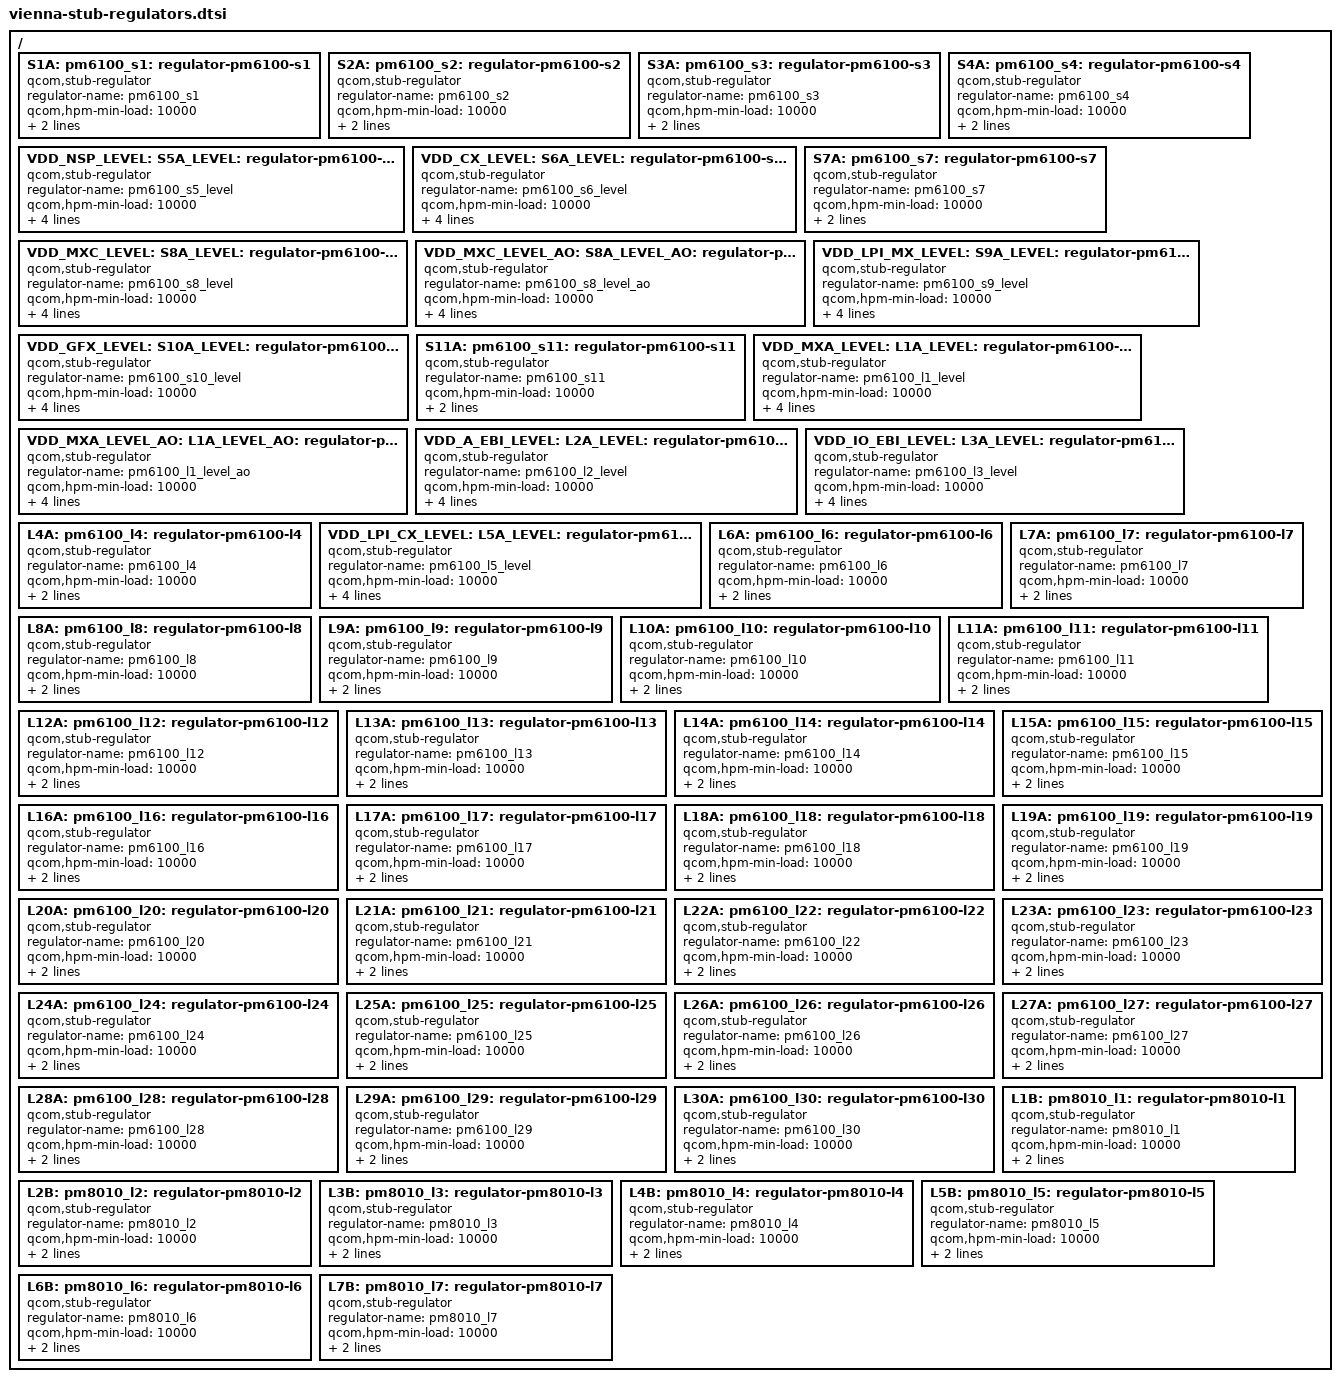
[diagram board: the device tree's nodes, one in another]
// SPDX-License-Identifier: BSD-3-Clause
/*
 * Copyright (c) 2024 Qualcomm Innovation Center, Inc. All rights reserved.
 */

#include <dt-bindings/regulator/qcom,rpmh-regulator-levels.h>

/ {
		S1A:
		pm6100_s1: regulator-pm6100-s1 {
			compatible = "qcom,stub-regulator";
			regulator-name = "pm6100_s1";
			qcom,hpm-min-load = <10000>;
			regulator-min-microvolt = <1700000>;
			regulator-max-microvolt = <1900000>;
		};

		S2A:
		pm6100_s2: regulator-pm6100-s2 {
			compatible = "qcom,stub-regulator";
			regulator-name = "pm6100_s2";
			qcom,hpm-min-load = <10000>;
			regulator-min-microvolt = <1010000>;
			regulator-max-microvolt = <1120000>;
		};

		S3A:
		pm6100_s3: regulator-pm6100-s3 {
			compatible = "qcom,stub-regulator";
			regulator-name = "pm6100_s3";
			qcom,hpm-min-load = <10000>;
			regulator-min-microvolt = <516000>;
			regulator-max-microvolt = <856000>;
		};

		S4A:
		pm6100_s4: regulator-pm6100-s4 {
			compatible = "qcom,stub-regulator";
			regulator-name = "pm6100_s4";
			qcom,hpm-min-load = <10000>;
			regulator-min-microvolt = <516000>;
			regulator-max-microvolt = <856000>;
		};

		VDD_NSP_LEVEL:
		S5A_LEVEL:
		pm6100_s5_level: regulator-pm6100-s5-level {
			compatible = "qcom,stub-regulator";
			regulator-name = "pm6100_s5_level";
			qcom,hpm-min-load = <10000>;
			regulator-min-microvolt =
				<RPMH_REGULATOR_LEVEL_RETENTION>;
			regulator-max-microvolt = <RPMH_REGULATOR_LEVEL_MAX>;
		};

		VDD_CX_LEVEL:
		S6A_LEVEL:
		pm6100_s6_level: regulator-pm6100-s6-level {
			compatible = "qcom,stub-regulator";
			regulator-name = "pm6100_s6_level";
			qcom,hpm-min-load = <10000>;
			regulator-min-microvolt =
				<RPMH_REGULATOR_LEVEL_RETENTION>;
			regulator-max-microvolt = <RPMH_REGULATOR_LEVEL_MAX>;
		};

		S7A:
		pm6100_s7: regulator-pm6100-s7 {
			compatible = "qcom,stub-regulator";
			regulator-name = "pm6100_s7";
			qcom,hpm-min-load = <10000>;
			regulator-min-microvolt = <565000>;
			regulator-max-microvolt = <960000>;
		};

		VDD_MXC_LEVEL:
		S8A_LEVEL:
		pm6100_s8_level: regulator-pm6100-s8-level {
			compatible = "qcom,stub-regulator";
			regulator-name = "pm6100_s8_level";
			qcom,hpm-min-load = <10000>;
			regulator-min-microvolt =
				<RPMH_REGULATOR_LEVEL_RETENTION>;
			regulator-max-microvolt = <RPMH_REGULATOR_LEVEL_MAX>;
		};

		VDD_MXC_LEVEL_AO:
		S8A_LEVEL_AO:
		pm6100_s8_level_ao: regulator-pm6100-s8-level-ao {
			compatible = "qcom,stub-regulator";
			regulator-name = "pm6100_s8_level_ao";
			qcom,hpm-min-load = <10000>;
			regulator-min-microvolt =
				<RPMH_REGULATOR_LEVEL_RETENTION>;
			regulator-max-microvolt = <RPMH_REGULATOR_LEVEL_MAX>;
		};

		VDD_LPI_MX_LEVEL:
		S9A_LEVEL:
		pm6100_s9_level: regulator-pm6100-s9-level {
			compatible = "qcom,stub-regulator";
			regulator-name = "pm6100_s9_level";
			qcom,hpm-min-load = <10000>;
			regulator-min-microvolt =
				<RPMH_REGULATOR_LEVEL_RETENTION>;
			regulator-max-microvolt = <RPMH_REGULATOR_LEVEL_MAX>;
		};

		VDD_GFX_LEVEL:
		S10A_LEVEL:
		pm6100_s10_level: regulator-pm6100-s10-level {
			compatible = "qcom,stub-regulator";
			regulator-name = "pm6100_s10_level";
			qcom,hpm-min-load = <10000>;
			regulator-min-microvolt =
				<RPMH_REGULATOR_LEVEL_RETENTION>;
			regulator-max-microvolt = <RPMH_REGULATOR_LEVEL_MAX>;
		};

		S11A:
		pm6100_s11: regulator-pm6100-s11 {
			compatible = "qcom,stub-regulator";
			regulator-name = "pm6100_s11";
			qcom,hpm-min-load = <10000>;
			regulator-min-microvolt = <1200000>;
			regulator-max-microvolt = <1320000>;
		};

		VDD_MXA_LEVEL:
		L1A_LEVEL:
		pm6100_l1_level: regulator-pm6100-l1-level {
			compatible = "qcom,stub-regulator";
			regulator-name = "pm6100_l1_level";
			qcom,hpm-min-load = <10000>;
			regulator-min-microvolt =
				<RPMH_REGULATOR_LEVEL_RETENTION>;
			regulator-max-microvolt = <RPMH_REGULATOR_LEVEL_MAX>;
		};

		VDD_MXA_LEVEL_AO:
		L1A_LEVEL_AO:
		pm6100_l1_level_ao: regulator-pm6100-l1-level-ao {
			compatible = "qcom,stub-regulator";
			regulator-name = "pm6100_l1_level_ao";
			qcom,hpm-min-load = <10000>;
			regulator-min-microvolt =
				<RPMH_REGULATOR_LEVEL_RETENTION>;
			regulator-max-microvolt = <RPMH_REGULATOR_LEVEL_MAX>;
		};

		VDD_A_EBI_LEVEL:
		L2A_LEVEL:
		pm6100_l2_level: regulator-pm6100-l2-level {
			compatible = "qcom,stub-regulator";
			regulator-name = "pm6100_l2_level";
			qcom,hpm-min-load = <10000>;
			regulator-min-microvolt =
				<RPMH_REGULATOR_LEVEL_RETENTION>;
			regulator-max-microvolt = <RPMH_REGULATOR_LEVEL_MAX>;
		};

		VDD_IO_EBI_LEVEL:
		L3A_LEVEL:
			pm6100_l3_level: regulator-pm6100-l3-level {
			compatible = "qcom,stub-regulator";
			regulator-name = "pm6100_l3_level";
			qcom,hpm-min-load = <10000>;
			regulator-min-microvolt =
				<RPMH_REGULATOR_LEVEL_RETENTION>;
			regulator-max-microvolt = <RPMH_REGULATOR_LEVEL_MAX>;
		};

		L4A:
		pm6100_l4: regulator-pm6100-l4 {
			compatible = "qcom,stub-regulator";
			regulator-name = "pm6100_l4";
			qcom,hpm-min-load = <10000>;
			regulator-min-microvolt = <751000>;
			regulator-max-microvolt = <824000>;
		};

		VDD_LPI_CX_LEVEL:
		L5A_LEVEL:
		pm6100_l5_level: regulator-pm6100-l5-level {
			compatible = "qcom,stub-regulator";
			regulator-name = "pm6100_l5_level";
			qcom,hpm-min-load = <10000>;
			regulator-min-microvolt =
				<RPMH_REGULATOR_LEVEL_RETENTION>;
			regulator-max-microvolt = <RPMH_REGULATOR_LEVEL_MAX>;
		};

		L6A:
		pm6100_l6: regulator-pm6100-l6 {
			compatible = "qcom,stub-regulator";
			regulator-name = "pm6100_l6";
			qcom,hpm-min-load = <10000>;
			regulator-min-microvolt = <1080000>;
			regulator-max-microvolt = <1350000>;
		};

		L7A:
		pm6100_l7: regulator-pm6100-l7 {
			compatible = "qcom,stub-regulator";
			regulator-name = "pm6100_l7";
			qcom,hpm-min-load = <10000>;
			regulator-min-microvolt = <1080000>;
			regulator-max-microvolt = <1320000>;
		};

		L8A:
		pm6100_l8: regulator-pm6100-l8 {
			compatible = "qcom,stub-regulator";
			regulator-name = "pm6100_l8";
			qcom,hpm-min-load = <10000>;
			regulator-min-microvolt = <1100000>;
			regulator-max-microvolt = <1400000>;
		};

		L9A:
		pm6100_l9: regulator-pm6100-l9 {
			compatible = "qcom,stub-regulator";
			regulator-name = "pm6100_l9";
			qcom,hpm-min-load = <10000>;
			regulator-min-microvolt = <950000>;
			regulator-max-microvolt = <1150000>;
		};

		L10A:
		pm6100_l10: regulator-pm6100-l10 {
			compatible = "qcom,stub-regulator";
			regulator-name = "pm6100_l10";
			qcom,hpm-min-load = <10000>;
			regulator-min-microvolt = <1698000>;
			regulator-max-microvolt = <1900000>;
		};

		L11A:
		pm6100_l11: regulator-pm6100-l11 {
			compatible = "qcom,stub-regulator";
			regulator-name = "pm6100_l11";
			qcom,hpm-min-load = <10000>;
			regulator-min-microvolt = <1500000>;
			regulator-max-microvolt = <2000000>;
		};

		L12A:
		pm6100_l12: regulator-pm6100-l12 {
			compatible = "qcom,stub-regulator";
			regulator-name = "pm6100_l12";
			qcom,hpm-min-load = <10000>;
			regulator-min-microvolt = <1700000>;
			regulator-max-microvolt = <1950000>;
		};

		L13A:
		pm6100_l13: regulator-pm6100-l13 {
			compatible = "qcom,stub-regulator";
			regulator-name = "pm6100_l13";
			qcom,hpm-min-load = <10000>;
			regulator-min-microvolt = <1080000>;
			regulator-max-microvolt = <2000000>;
		};

		L14A:
		pm6100_l14: regulator-pm6100-l14 {
			compatible = "qcom,stub-regulator";
			regulator-name = "pm6100_l14";
			qcom,hpm-min-load = <10000>;
			regulator-min-microvolt = <1080000>;
			regulator-max-microvolt = <2000000>;
		};

		L15A:
		pm6100_l15: regulator-pm6100-l15 {
			compatible = "qcom,stub-regulator";
			regulator-name = "pm6100_l15";
			qcom,hpm-min-load = <10000>;
			regulator-min-microvolt = <320000>;
			regulator-max-microvolt = <2000000>;
		};

		L16A:
		pm6100_l16: regulator-pm6100-l16 {
			compatible = "qcom,stub-regulator";
			regulator-name = "pm6100_l16";
			qcom,hpm-min-load = <10000>;
			regulator-min-microvolt = <1700000>;
			regulator-max-microvolt = <1950000>;
		};

		L17A:
		pm6100_l17: regulator-pm6100-l17 {
			compatible = "qcom,stub-regulator";
			regulator-name = "pm6100_l17";
			qcom,hpm-min-load = <10000>;
			regulator-min-microvolt = <1504000>;
			regulator-max-microvolt = <3300000>;
		};

		L18A:
		pm6100_l18: regulator-pm6100-l18 {
			compatible = "qcom,stub-regulator";
			regulator-name = "pm6100_l18";
			qcom,hpm-min-load = <10000>;
			regulator-min-microvolt = <1710000>;
			regulator-max-microvolt = <1890000>;
		};

		L19A:
		pm6100_l19: regulator-pm6100-l19 {
			compatible = "qcom,stub-regulator";
			regulator-name = "pm6100_l19";
			qcom,hpm-min-load = <10000>;
			regulator-min-microvolt = <2850000>;
			regulator-max-microvolt = <3544000>;
		};

		L20A:
		pm6100_l20: regulator-pm6100-l20 {
			compatible = "qcom,stub-regulator";
			regulator-name = "pm6100_l20";
			qcom,hpm-min-load = <10000>;
			regulator-min-microvolt = <2700000>;
			regulator-max-microvolt = <3544000>;
		};

		L21A:
		pm6100_l21: regulator-pm6100-l21 {
			compatible = "qcom,stub-regulator";
			regulator-name = "pm6100_l21";
			qcom,hpm-min-load = <10000>;
			regulator-min-microvolt = <1504000>;
			regulator-max-microvolt = <3544000>;
		};

		L22A:
		pm6100_l22: regulator-pm6100-l22 {
			compatible = "qcom,stub-regulator";
			regulator-name = "pm6100_l22";
			qcom,hpm-min-load = <10000>;
			regulator-min-microvolt = <3300000>;
			regulator-max-microvolt = <5000000>;
		};

		L23A:
		pm6100_l23: regulator-pm6100-l23 {
			compatible = "qcom,stub-regulator";
			regulator-name = "pm6100_l23";
			qcom,hpm-min-load = <10000>;
			regulator-min-microvolt = <2700000>;
			regulator-max-microvolt = <2900000>;
		};

		L24A:
		pm6100_l24: regulator-pm6100-l24 {
			compatible = "qcom,stub-regulator";
			regulator-name = "pm6100_l24";
			qcom,hpm-min-load = <10000>;
			regulator-min-microvolt = <870000>;
			regulator-max-microvolt = <970000>;
		};

		L25A:
		pm6100_l25: regulator-pm6100-l25 {
			compatible = "qcom,stub-regulator";
			regulator-name = "pm6100_l25";
			qcom,hpm-min-load = <10000>;
			regulator-min-microvolt = <720000>;
			regulator-max-microvolt = <1050000>;
		};

		L26A:
		pm6100_l26: regulator-pm6100-l26 {
			compatible = "qcom,stub-regulator";
			regulator-name = "pm6100_l26";
			qcom,hpm-min-load = <10000>;
			regulator-min-microvolt = <1100000>;
			regulator-max-microvolt = <1300000>;
		};

		L27A:
		pm6100_l27: regulator-pm6100-l27 {
			compatible = "qcom,stub-regulator";
			regulator-name = "pm6100_l27";
			qcom,hpm-min-load = <10000>;
			regulator-min-microvolt = <1200000>;
			regulator-max-microvolt = <1320000>;
		};

		L28A:
		pm6100_l28: regulator-pm6100-l28 {
			compatible = "qcom,stub-regulator";
			regulator-name = "pm6100_l28";
			qcom,hpm-min-load = <10000>;
			regulator-min-microvolt = <1600000>;
			regulator-max-microvolt = <2000000>;
		};

		L29A:
		pm6100_l29: regulator-pm6100-l29 {
			compatible = "qcom,stub-regulator";
			regulator-name = "pm6100_l29";
			qcom,hpm-min-load = <10000>;
			regulator-min-microvolt = <1080000>;
			regulator-max-microvolt = <1900000>;
		};

		L30A:
		pm6100_l30: regulator-pm6100-l30 {
			compatible = "qcom,stub-regulator";
			regulator-name = "pm6100_l30";
			qcom,hpm-min-load = <10000>;
			regulator-min-microvolt = <1504000>;
			regulator-max-microvolt = <3544000>;
		};

		L1B:
		pm8010_l1: regulator-pm8010-l1 {
			compatible = "qcom,stub-regulator";
			regulator-name = "pm8010_l1";
			qcom,hpm-min-load = <10000>;
			regulator-min-microvolt = <528000>;
			regulator-max-microvolt = <1544000>;
		};

		L2B:
		pm8010_l2: regulator-pm8010-l2 {
			compatible = "qcom,stub-regulator";
			regulator-name = "pm8010_l2";
			qcom,hpm-min-load = <10000>;
			regulator-min-microvolt = <950000>;
			regulator-max-microvolt = <1150000>;
		};

		L3B:
		pm8010_l3: regulator-pm8010-l3 {
			compatible = "qcom,stub-regulator";
			regulator-name = "pm8010_l3";
			qcom,hpm-min-load = <10000>;
			regulator-min-microvolt = <1792000>;
			regulator-max-microvolt = <1900000>;
		};

		L4B:
		pm8010_l4: regulator-pm8010-l4 {
			compatible = "qcom,stub-regulator";
			regulator-name = "pm8010_l4";
			qcom,hpm-min-load = <10000>;
			regulator-min-microvolt = <1792000>;
			regulator-max-microvolt = <1900000>;
		};

		L5B:
		pm8010_l5: regulator-pm8010-l5 {
			compatible = "qcom,stub-regulator";
			regulator-name = "pm8010_l5";
			qcom,hpm-min-load = <10000>;
			regulator-min-microvolt = <2700000>;
			regulator-max-microvolt = <2900000>;
		};

		L6B:
		pm8010_l6: regulator-pm8010-l6 {
			compatible = "qcom,stub-regulator";
			regulator-name = "pm8010_l6";
			qcom,hpm-min-load = <10000>;
			regulator-min-microvolt = <1792000>;
			regulator-max-microvolt = <3312000>;
		};

		L7B:
		pm8010_l7: regulator-pm8010-l7 {
			compatible = "qcom,stub-regulator";
			regulator-name = "pm8010_l7";
			qcom,hpm-min-load = <10000>;
			regulator-min-microvolt = <1504000>;
			regulator-max-microvolt = <3544000>;
		};
};
